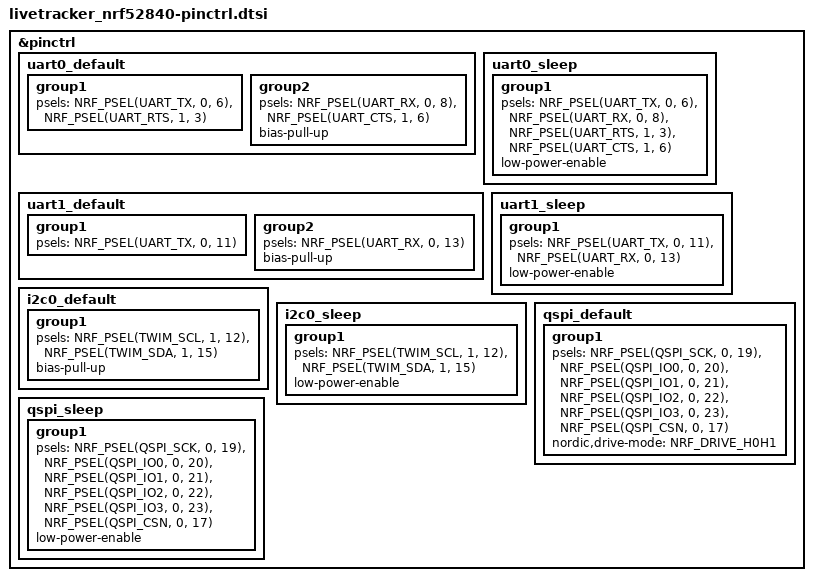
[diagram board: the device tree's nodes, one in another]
/*
 * LiveTracker nRF52840 Pin Control Configuration
 *
 * Copyright (c) 2026 nRFModule
 * SPDX-License-Identifier: Apache-2.0
 *
 * Pin mapping derived from LiveTracker schematic (nRF_tracker.NET)
 * nRF52840 WLCSP BGA100 package
 */

&pinctrl {
	/*
	 * Serial Modem UART (nRF52840 <-> nRF9151)
	 * 
	 * UART without hardware flow control:
	 *   TX:  P0.06 -> nRF9151 P0.11 (RX)
	 *   RX:  P0.08 <- nRF9151 P0.10 (TX)
	 *
	 * To enable HW flow control, uncomment RTS/CTS lines:
	 *   RTS: P1.03 -> nRF9151 P0.12
	 *   CTS: P1.06 <- nRF9151 P0.09
	 */
	uart0_default: uart0_default {
		group1 {
			psels = <NRF_PSEL(UART_TX, 0, 6)>,
			<NRF_PSEL(UART_RTS, 1, 3)>;   /* Uncomment for HW flow control */
		};
		group2 {
			psels = <NRF_PSEL(UART_RX, 0, 8)>,
			<NRF_PSEL(UART_CTS, 1, 6)>;   /* Uncomment for HW flow control */
			bias-pull-up;
		};
	};

	uart0_sleep: uart0_sleep {
		group1 {
			psels = <NRF_PSEL(UART_TX, 0, 6)>,
				<NRF_PSEL(UART_RX, 0, 8)>,
			<NRF_PSEL(UART_RTS, 1, 3)>,
			<NRF_PSEL(UART_CTS, 1, 6)>;
			low-power-enable;
		};
	};

	/*
	 * GPS UART (nRF52840 <-> L76-L GPS Module)
	 *
	 * nRF52840 Ball H7 (P0.13) <- GPS TX (we receive GPS data)
	 * nRF52840 Ball H8 (P0.11) -> GPS RX (we send commands to GPS)
	 */
	uart1_default: uart1_default {
		group1 {
			psels = <NRF_PSEL(UART_TX, 0, 11)>;
		};
		group2 {
			psels = <NRF_PSEL(UART_RX, 0, 13)>;
			bias-pull-up;
		};
	};

	uart1_sleep: uart1_sleep {
		group1 {
			psels = <NRF_PSEL(UART_TX, 0, 11)>,
				<NRF_PSEL(UART_RX, 0, 13)>;
			low-power-enable;
		};
	};

	/*
	 * I2C0 for Sensors (LIS2DH12 Accelerometer, BMP390 Barometer)
	 *
	 * nRF52840 Ball C5 (P1.12) = SCL
	 * nRF52840 Ball C6 (P1.15) = SDA
	 */
	i2c0_default: i2c0_default {
		group1 {
			psels = <NRF_PSEL(TWIM_SCL, 1, 12)>,
				<NRF_PSEL(TWIM_SDA, 1, 15)>;
			bias-pull-up;
		};
	};

	i2c0_sleep: i2c0_sleep {
		group1 {
			psels = <NRF_PSEL(TWIM_SCL, 1, 12)>,
				<NRF_PSEL(TWIM_SDA, 1, 15)>;
			low-power-enable;
		};
	};

	/*
	 * QSPI for External Flash (MX25R6435F - 8MB)
	 *
	 * nRF52840 Ball K4 (P0.19) = SCK
	 * nRF52840 Ball J6 (P0.17) = CS
	 * nRF52840 Ball J5 (P0.20) = DIO0/MOSI
	 * nRF52840 Ball J4 (P0.21) = DIO1/MISO
	 * nRF52840 Ball K3 (P0.22) = DIO2/WP
	 * nRF52840 Ball H5 (P0.23) = DIO3/HOLD
	 */
	qspi_default: qspi_default {
		group1 {
			psels = <NRF_PSEL(QSPI_SCK, 0, 19)>,
				<NRF_PSEL(QSPI_IO0, 0, 20)>,
				<NRF_PSEL(QSPI_IO1, 0, 21)>,
				<NRF_PSEL(QSPI_IO2, 0, 22)>,
				<NRF_PSEL(QSPI_IO3, 0, 23)>,
				<NRF_PSEL(QSPI_CSN, 0, 17)>;
			nordic,drive-mode = <NRF_DRIVE_H0H1>;
		};
	};

	qspi_sleep: qspi_sleep {
		group1 {
			psels = <NRF_PSEL(QSPI_SCK, 0, 19)>,
				<NRF_PSEL(QSPI_IO0, 0, 20)>,
				<NRF_PSEL(QSPI_IO1, 0, 21)>,
				<NRF_PSEL(QSPI_IO2, 0, 22)>,
				<NRF_PSEL(QSPI_IO3, 0, 23)>,
				<NRF_PSEL(QSPI_CSN, 0, 17)>;
			low-power-enable;
		};
	};
};
